VERSION ""

NS_ :

BS_:

BU_: Motor

BO_ 290 Motor_CMD: 8 Vector__XXX
 SG_ Motor_Run_Rpm : 16|16@1- (1,0) [0|0] "" Vector__XXX
 SG_ Motor_Run_Req : 7|1@0+ (1,0) [0|0] "" Vector__XXX

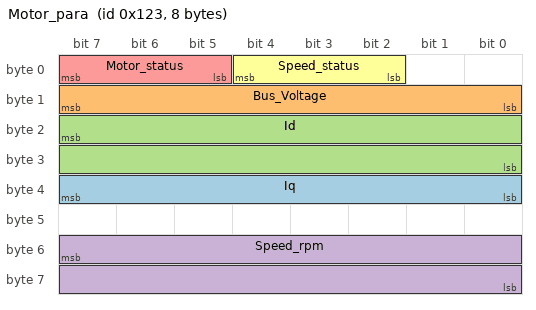
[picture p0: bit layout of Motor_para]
BO_ 291 Motor_para: 8 Vector__XXX
 SG_ Iq : 32|8@1- (1,0) [0|0] "" Vector__XXX
 SG_ Bus_Voltage : 8|8@1- (1,0) [0|0] "" Vector__XXX
 SG_ Id : 23|16@0+ (4,0) [0|65535] "" Vector__XXX
 SG_ Speed_rpm : 55|16@0+ (1,-80) [0|255] "" Vector__XXX
 SG_ Motor_status : 7|3@0+ (1,0) [0|0] "" Vector__XXX
 SG_ Speed_status : 4|3@0+ (1,0) [0|0] "" Vector__XXX

BA_DEF_ SG_  "GenSigSendType" ENUM  "Cyclic","OnWrite","OnWriteWithRepetition","OnChange","OnChangeWithRepetition","IfActive","IfActiveWithRepetition","NoSigSendType";
BA_DEF_ BO_  "GenMsgSendType" ENUM  "Cyclic","not_used","not_used","not_used","not_used","Cyclic","not_used","IfActive","NoMsgSendType";
BA_DEF_ BU_  "NmStationAddress" HEX 0 0;
BA_DEF_  "DBName" STRING ;
BA_DEF_  "BusType" STRING ;
BA_DEF_DEF_  "GenSigSendType" "Cyclic";
BA_DEF_DEF_  "GenMsgSendType" "NoMsgSendType";
BA_DEF_DEF_  "NmStationAddress" 0;
BA_DEF_DEF_  "DBName" "";
BA_DEF_DEF_  "BusType" "CAN";
BA_ "DBName" "Test";
BA_ "NmStationAddress" BU_ Motor 1;
